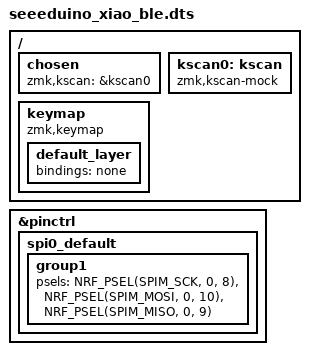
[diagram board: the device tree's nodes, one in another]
#include <seeeduino_xiao_ble-pinctrl.dtsi>

&pinctrl {
    spi0_default: spi0_default {
        group1 {
            psels = <NRF_PSEL(SPIM_SCK, 0, 8)>,
                    <NRF_PSEL(SPIM_MOSI, 0, 10)>,
                    <NRF_PSEL(SPIM_MISO, 0, 9)>;
        };
    };
};

/ {
    chosen {
        zmk,kscan = &kscan0;
    };

    kscan0: kscan {
        compatible = "zmk,kscan-mock";
    };

    keymap {
        compatible = "zmk,keymap";
        default_layer {
            bindings = <&none>;
        };
    };
};
